# PIC32MK0128MCA032 device description
Architecture: MIPS; Family: PIC32MK; Series: PIC32MK
Registers are 32-bit, read-write, no defined reset value unless marked. A register's access mark holds for its fields unless they carry their own. Offsets are from the block's base; [hi:lo] are bit positions; {n}, {i} and the like mark numbered series; 'fields as' and 'values as' point back to an identical list.

## ADCHS
Instances: ADCHS 0x1f887000 in periph_pb5_std
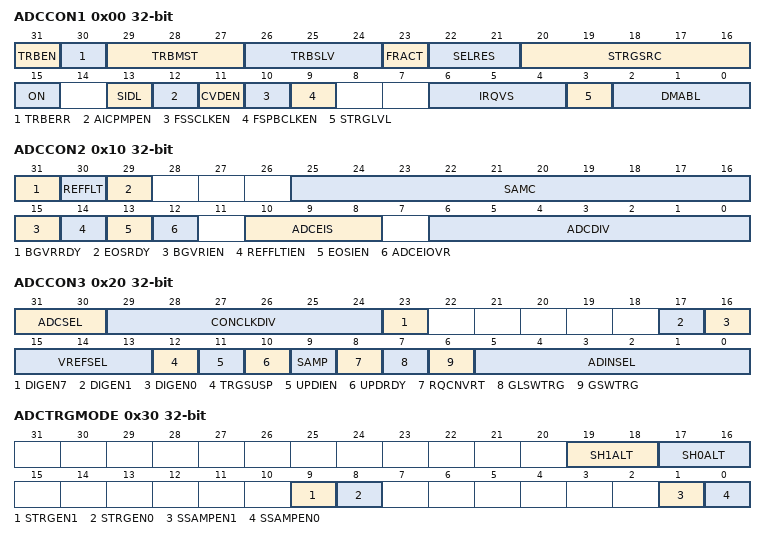
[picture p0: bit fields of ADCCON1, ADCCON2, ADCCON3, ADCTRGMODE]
0x00 ADCCON1 — ADC Control Register 1
  [31] TRBEN
  [30] TRBERR
  [29:27] TRBMST
  [26:24] TRBSLV
  [23] FRACT — Fractional Data Output Format bit
    1=Fractional; 0=Integer
  [22:21] SELRES — Shared ADC7 Resolution bits
    3=12 bits (default); 2=10 bits; 1=8 bits; 0=6 bits
  [20:16] STRGSRC — Scan Trigger Source Select bits
    {v}=PWM Generator {v-23} Current-Limit (v=24..27); 20=CTMU trip; {v}=Output Compare {v-15} period end (v=16..19); {v}=PWM Generator {v-9} trigger (v=10..13); 9=Secondary PWM time base; 8=Primary PWM time base; 7=General Purpose Timer5; 6=General Purpose Timer3; 5=General Purpose Timer1; 4=INT0; 2=Software level trigger; 1=Software edge trigger; 0=No Trigger
  [15] ON — ADC Module Enable bit
    1=ADC module is enabled; 0=ADC module is disabled
  [13] SIDL — Stop in Idle Mode bit
    1=Discontinue module operation when device enters Idle mode; 0=Continue module operation in Idle mode
  [12] AICPMPEN — Analog Input Charge Pump Enable bit
    1=Analog input charge pump is enabled; 0=Analog input charge pump is disabled (default)
  [11] CVDEN — Capacitive Voltage Division Enable bit
    1=CVD operation is enabled; 0=CVD operation is disabled
  [10] FSSCLKEN — Fast Synchronous System Clock to ADC Control Clock bit
    1=Bypass synchronizer logic for DMA system clock to ADC control clocks; 0=Enable clock synchronizers for non-synchronized DMA to ADC clock sources
  [9] FSPBCLKEN — Fast Synchronous Peripheral Clock to ADC Control Clock bit
    1=Bypass synchronizer logic for peripheral clock to ADC control clocks; 0=Enable clock synchronizers for non-synchronized peripheral clock to ADC control clocks
  [6:4] IRQVS — Interrupt Vector Shift bits
    {v}=Shift x left {v} bit position (v=0..7)
  [3] STRGLVL — Scan Trigger High Level/Positive Edge Sensitivity bit
    1=Scan trigger is high level sensitive. Once STRIG mode is selected the scan trigger will continue for all selected analog inputs; 0=Scan trigger is positive edge sensitive. Once STRIG mode is selected only a single scan trigger will be generated which will complete the scan of all selected analog inputs. (TRGSRCx in the ADCTRGx register)
  [2:0] DMABL — DMA to System RAM Buffer Length Size bits
    7=Allocates 128 locations in system memory to each analog input; 6=Allocates 64 locations in system memory to each analog input; 5=Allocates 32 locations in system memory to each analog input; 4=Allocates 16 locations in system memory to each analog input; 3=Allocates 8 locations in system memory to each analog input; 2=Allocates 4 locations in system memory to each analog input; 1=Allocates 2 locations in system memory to each analog input; 0=Allocates 1 location in system memory to each analog input
0x10 ADCCON2 — ADC Control Register 2
  [31] BGVRRDY — Band Gap Voltage/ADC Reference Voltage Status bit
    1=Both band gap voltage and ADC reference voltages (Vref) are ready; 0=Either or both band gap voltage and ADC reference voltages (Vref) are not ready
  [30] REFFLT — Band Gap/ Vref / AVdd BOR Fault Status bit
    1=Fault in band gap or the Vref voltage while the ON bit (ADCCON1) was set. Most likely a band gap or Vref fault will be caused by a BOR of the analog Vdd supply.; 0=Band gap and Vref voltage are working properly
  [29] EOSRDY — End of Scan Interrupt Status bit
    1=All analog inputs are considered for scanning through the scan trigger (all analog inputs specified in the ADCCSS1 and ADCCSS2 registers) have completed scanning; 0=Scanning has not completed
  [25:16] SAMC — Sample Time for the Shared ADC (ADC7) bits
    0x3ff=1025 Tad; 1=3 Tad; 0=2 Tad
  [15] BGVRIEN — Band Gap/ Vref Voltage Ready Interrupt Enable bit
    1=Interrupt will be generated when the BGVRDDY bit is set; 0=No interrupt is generated when the BGVRRDY bit is set
  [14] REFFLTIEN — Band Gap/ Vref Voltage Fault Interrupt Enable bit
    1=Interrupt will be generated when the REFFLT bit is set; 0=No interrupt is generated when the REFFLT bit is set
  [13] EOSIEN — End of Scan Interrupt Enable bit
    1=Interrupt will be generated when EOSRDY bit is set; 0=No interrupt is generated when the EOSRDY bit is set
  [12] ADCEIOVR — Early Interrupt Request Override bit
    1=Early interrupt generation is overridden and interrupt generation is controlled by the ADCGIRQEN1 and ADCGIRQEN2 registers; 0=Early interrupt generation is not overridden and interrupt generation is controlled by the ADCEIEN1 and ADCEIEN2 registers
  [10:8] ADCEIS — Shared ADC Early Interrupt Select bits
    {v}=The data ready interrupt is generated {v+1} ADC clocks prior to end of conversion (v=2..7); 1=The data ready interrupt is generated 2 ADC module clocks prior to end of conversion; 0=The data ready interrupt is generated 1 ADC module clock prior to end of conversion
  [6:0] ADCDIV — Shared ADC Clock Divider bits
    127=254 * Tq = Tad; 3=6 * Tq = Tad; 2=4 * Tq = Tad; 1=2 * Tq = Tad
0x20 ADCCON3 — ADC Control Register 3
  [31:30] ADCSEL — Analog-to-Digital Clock Source bits
    3=SYSCLK (Required if using DMA for ADC); 2=REFCLK3; 1=FRC; 0=SYSCLK
  [29:24] CONCLKDIV — Analog-to-Digital Control Clock Divider bits
    63=126 * Tclk = Tq; 3=6 * Tclk = Tq; 2=4 * Tclk = Tq; 1=2 * Tclk = Tq; 0=Tclk = Tq
  [23] DIGEN7 — ADC2 Digital Enable bit
    1=ADC2 is digital enabled (required for active operation); 0=ADC2 is digital disabled (power-saving mode)
  [17] DIGEN1 — ADC1 Digital Enable bit
    1=ADC1 is digital enabled (required for active operation); 0=ADC1 is digital disabled (power-saving mode)
  [16] DIGEN0 — ADC0 Digital Enable bit
    1=ADC0 is digital enabled (required for active operation); 0=ADC0 is digital disabled (power-saving mode)
  [15:13] VREFSEL — Voltage Reference Input Selection bits
    3=ADC VREFH is VREF+, ADC VREFL is VREF-; 2=ADC VREFH is AVDD, ADC VREFL is VREF-; 1=ADC VREFH is VREF+, ADC VREFL is AVSS; 0=ADC VREFH is AVDD, ADC VREFL is AVSS
  [12] TRGSUSP — Trigger Suspend bit
    1=Triggers are blocked from starting a new analog-to-digital conversion; 0=Triggers are not blocked
  [11] UPDIEN — Update Ready Interrupt Enable bit
    1=Interrupt will be generated when the UPDRDY bit is set by hardware; 0=No interrupt is generated
  [10] UPDRDY — ADC Update Ready Status bit
    1=ADC SFRs can be updated; 0=ADC SFRs cannot be updated
  [9] SAMP — Shared ADC7 Analog Input Sampling Enable bit
    1=The ADC S&H amplifier is sampling; 0=The ADC S&H amplifier is holding
  [8] RQCNVRT — Individual ADC Input Conversion Request bit
    1=Trigger the conversion of the selected ADC input as specified by the ADINSEL bits; 0=Do not trigger the conversion
  [7] GLSWTRG — Global Level Software Trigger bit
    1=Trigger conversion for ADC inputs that have selected the GLSWTRG bit as the trigger signal; 0=Do not trigger an analog-to-digital conversion
  [6] GSWTRG — Global Software Trigger bit
    1=Trigger conversion for ADC inputs that have selected the GSWTRG bit as either through the associated TRGSRC bits in the ADCTRGx registers or through the STRGSRC(4:0) bits in the ADCCON1 register the trigger signal
  [5:0] ADINSEL — Analog Input Select bits
    53=CTMU Temperature Sensor (internal AN53); 50=IVref 1.2V (internal AN50); {v}=AN{v} (v=0..17)
0x30 ADCTRGMODE — ADC Triggering Mode for Dedicated ADC Register
  [19:18] SH1ALT — ADC1 Analog Input Select bit
    3=AN16; 2=AN5; 1=AN3; 0=AN1
  [17:16] SH0ALT — ADC0 Analog Input Select bit
    3=AN6; 2=AN4; 1=AN13; 0=AN0
  [9] STRGEN1 — ADC1 Presynchronized Triggers bit
    1=ADC1 uses presynchronized triggers; 0=ADC1 does not use presynchronized triggers
  [8] STRGEN0 — ADC0 Presynchronized Triggers bit
    1=ADC0 uses presynchronized triggers; 0=ADC0 does not use presynchronized triggers
  [1] SSAMPEN1 — ADC1 Synchronous Sampling bit
    1=ADC1 uses synchronous sampling for the first sample after being idle or disabled; 0=ADC1 does not use synchronous sampling
  [0] SSAMPEN0 — ADC0 Synchronous Sampling bit
    1=ADC0 uses synchronous sampling for the first sample after being idle or disabled; 0=ADC0 does not use synchronous sampling
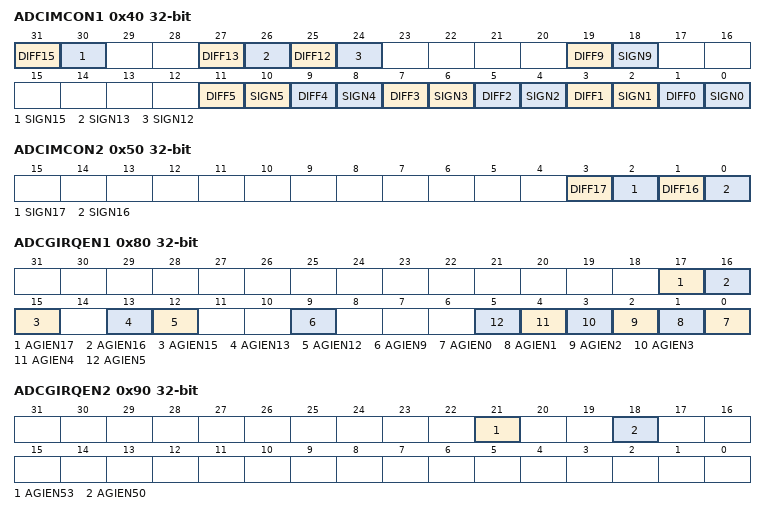
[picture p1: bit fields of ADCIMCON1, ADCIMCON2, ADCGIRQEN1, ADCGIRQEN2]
0x40 ADCIMCON1 — ADC Input Mode Control Register 1
  [31] DIFF15 — AN15 Mode bit
    1=Selects AN15 differential input pair as AN15+ and AN1-; 0=AN15 is using Single-ended mode
  [30] SIGN15 — AN15 Signed Data Mode bit
    1=AN15 is using Signed Data mode; 0=AN15 is using Unsigned Data mode
  [27] DIFF13 — AN13 Mode bit
    1=Selects AN13 differential input pair as AN13+ and AN1-; 0=AN13 is using Single-ended mode
  [26] SIGN13 — AN13 Signed Data Mode bit
    1=AN13 is using Signed Data mode; 0=AN13 is using Unsigned Data mode
  [25] DIFF12 — AN12 Mode bit
    1=Selects AN12 differential input pair as AN12+ and AN1-; 0=AN12 is using Single-ended mode
  [24] SIGN12 — AN12 Signed Data Mode bit
    1=AN12 is using Signed Data mode; 0=AN12 is using Unsigned Data mode
  [19] DIFF9 — AN9 Mode bit
    1=Selects AN9 differential input pair as AN9+ and AN1-; 0=AN9 is using Single-ended mode
  [18] SIGN9 — AN9 Signed Data Mode bit
    1=AN9 is using Signed Data mode; 0=AN9 is using Unsigned Data mode
  [11] DIFF5 — AN5 Mode bit
    1=Selects AN5 differential input pair as AN5+ and AN11-; 0=AN5 is using Single-ended mode
  [2n] SIGN{n} (n=0..5) — AN{n} Signed Data Mode bit
    1=AN{n} is using Signed Data mode; 0=AN{n} is using Unsigned Data mode
  [9] DIFF4 — AN4 Mode bit
    1=Selects AN4 differential input pair as AN4+ and AN10-; 0=AN4 is using Single-ended mode
  [7] DIFF3 — AN3 Mode bit
    1=Selects AN3 differential input pair as AN3+ and AN27-; 0=AN3 is using Single-ended mode
  [5] DIFF2 — AN2 Mode bit
    1=Selects AN2 differential input pair as AN2+ and AN8-; 0=AN2 is using Single-ended mode
  [3] DIFF1 — AN1 Mode bit
    1=Selects AN1 differential input pair as AN1+ and AN7-; 0=AN1 is using Single-ended mode
  [1] DIFF0 — AN0 Mode bit
    1=Selects AN0 differential input pair as AN0+ and AN6-; 0=AN0 is using Single-ended mode
0x50 ADCIMCON2 — ADC Input Mode Control Register 2
  [3] DIFF17 — AN17 Mode bit
    1=Selects AN17 differential pair input as AN17+ and AN1-; 0=AN17 is using Single-ended mode
  [2] SIGN17 — AN17 Signed Data Mode bit
    1=AN17 is using Signed Data mode; 0=AN17 is using Unsigned Data mode
  [1] DIFF16 — AN16 Mode bit
    1=Selects AN16 differential pair input as AN16+ and AN1-; 0=AN16 is using Single-ended mode
  [0] SIGN16 — AN16 Signed Data Mode bit
    1=AN16 is using Signed Data mode; 0=AN16 is using Unsigned Data mode
0x80 ADCGIRQEN1 — ADC Global Interrupt Enable Register 1
  [all] fields
    1=Interrupts are enabled for the selected analog input. The interrupt is generated after the converted data is ready (indicated by the AIRDYx bit of the ADCDSTAT1 register); 0=Interrupts are disabled
  [17] AGIEN17 — ADC Global Interrupt Enable bit
  [16] AGIEN16 — ADC Global Interrupt Enable bit
  [15] AGIEN15 — ADC Global Interrupt Enable bit
  [13] AGIEN13 — ADC Global Interrupt Enable bit
  [12] AGIEN12 — ADC Global Interrupt Enable bit
  [9] AGIEN9 — ADC Global Interrupt Enable bit
  [n] AGIEN{n} (n=0..5) — ADC Global Interrupt Enable bit
0x90 ADCGIRQEN2 — ADC Global Interrupt Enable Register 2
  [21] AGIEN53 — ADC Global Interrupt Enable bit
    values as the fields of ADCGIRQEN1
  [18] AGIEN50 — ADC Global Interrupt Enable bit
    values as the fields of ADCGIRQEN1
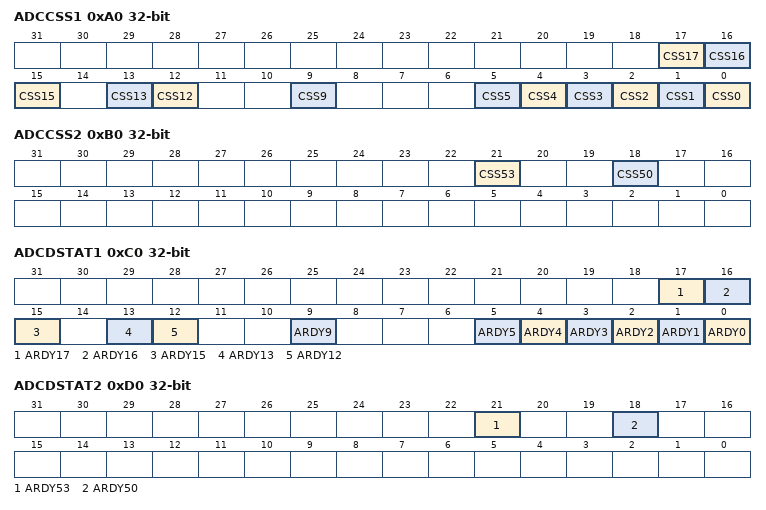
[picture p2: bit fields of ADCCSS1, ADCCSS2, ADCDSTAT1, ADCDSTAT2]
0xA0 ADCCSS1 — ADC Common Scan Select Register 1
  [all] fields
    1=Select ANx for input scan (i.e.ANx = CSSx and scan is sequential starting with the lowest to highest enabled CSSx analog input pin); 0=Skip ANx for input scan
  [17] CSS17 — Analog Common Scan Select bits
  [16] CSS16 — Analog Common Scan Select bits
  [15] CSS15 — Analog Common Scan Select bits
  [13] CSS13 — Analog Common Scan Select bits
  [12] CSS12 — Analog Common Scan Select bits
  [9] CSS9 — Analog Common Scan Select bits
  [n] CSS{n} (n=0..5) — Analog Common Scan Select bits
0xB0 ADCCSS2 — ADC Common Scan Select Register 2
  [21] CSS53 — Analog Common Scan Select bits
    values as the fields of ADCCSS1
  [18] CSS50 — Analog Common Scan Select bits
    values as the fields of ADCCSS1
0xC0 ADCDSTAT1 ro — ADC Data Ready Status Register 1
  [all] fields
    1=This bit is set when converted data is ready in the data register; 0=This bit is cleared when the associated data register is read
  [17] ARDY17 — Conversion Data Ready for Corresponding Analog Input Ready bits
  [16] ARDY16 — Conversion Data Ready for Corresponding Analog Input Ready bits
  [15] ARDY15 — Conversion Data Ready for Corresponding Analog Input Ready bits
  [13] ARDY13 — Conversion Data Ready for Corresponding Analog Input Ready bits
  [12] ARDY12 — Conversion Data Ready for Corresponding Analog Input Ready bits
  [9] ARDY9 — Conversion Data Ready for Corresponding Analog Input Ready bits
  [n] ARDY{n} (n=0..5) — Conversion Data Ready for Corresponding Analog Input Ready bits
0xD0 ADCDSTAT2 ro
  [21] ARDY53 — Conversion Data Ready for Corresponding Analog Input Ready bits
    values as the fields of ADCDSTAT1
  [18] ARDY50 — Conversion Data Ready for Corresponding Analog Input Ready bits
    values as the fields of ADCDSTAT1
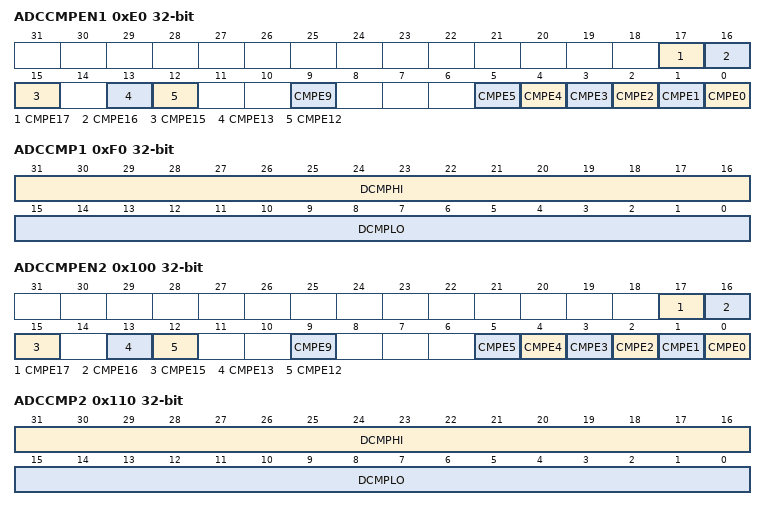
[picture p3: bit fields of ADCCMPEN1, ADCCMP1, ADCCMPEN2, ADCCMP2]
0xE0 ADCCMPEN1 — ADC Digital Comparator 'x' Enable Register ('x' = 1 through 4)
  [17] CMPE17, [16] CMPE16, [15] CMPE15, [13] CMPE13, [12] CMPE12, [9] CMPE9, [n] CMPE{n} (n=0..5)
0xF0 ADCCMP1
  [31:16] DCMPHI, [15:0] DCMPLO
0x100 ADCCMPEN2 — ADC Digital Comparator 'x' Enable Register ('x' = 1 through 4)
  fields as ADCCMPEN1
0x110 ADCCMP2
  [31:16] DCMPHI, [15:0] DCMPLO
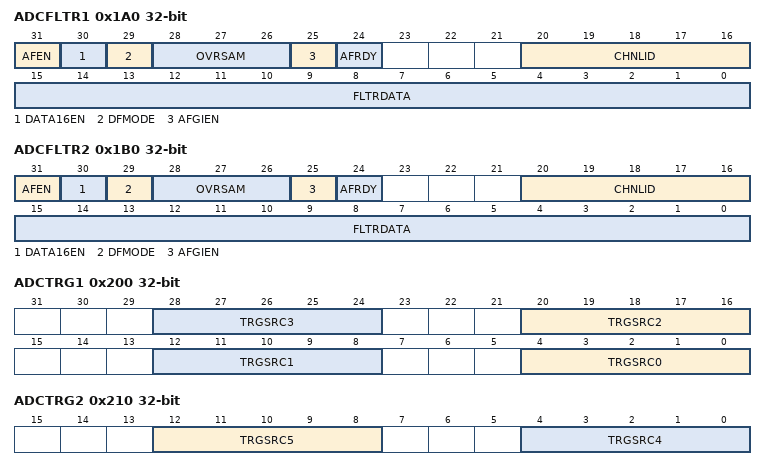
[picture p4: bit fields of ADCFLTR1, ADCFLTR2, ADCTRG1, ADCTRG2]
0x1A0 ADCFLTR1 — ADC Digital Filter Register
  [31] AFEN — Digital Filter 'x' Enable bit
    1=Digital filter is enabled; 0=Digital filter is disabled and the AFRDY status bit is cleared
  [30] DATA16EN — Filter Significant Data Length bit
    1=All 16 bits of the filter output data are significant; 0=Only the first 12 bits are significant
  [29] DFMODE — ADC Filter Mode bit
    1=Filter x works in Averaging mode; 0=Filter x works in Oversampling Filter mode (default)
  [28:26] OVRSAM — Oversampling Filter Ratio bits
    7=(If DFMODE is 0) 128 samples (shift sum 3 bits to right output data is in 15.1 format) / (If DFMODE is 1) 256 samples (256 samples to be averaged); 6=(If DFMODE is 0) 32 samples (shift sum 2 bits to right output data is in 14.1 format) / (If DFMODE is 1) 128 samples (128 samples to be averaged); 5=(If DFMODE is 0) 8 samples (shift sum 1 bit to right output data is in 13.1 format) / (If DFMODE is 1) 64 samples (64 samples to be averaged); 4=(If DFMODE is 0) 2 samples (shift sum 0 bits to right output data is in 12.1 format) / (If DFMODE is 1) 32 samples (32 samples to be averaged); 3=(If DFMODE is 0) 256 samples (shift sum 4 bits to right output data is 16 bits) / (If DFMODE is 1) 16 samples (16 samples to be averaged); 2=(If DFMODE is 0) 64 samples (shift sum 3 bits to right output data is 15 bits) / (If DFMODE is 1) 8 samples (8 samples to be averaged); 1=(If DFMODE is 0) 16 samples (shift sum 2 bits to right output data is 14 bits) / (If DFMODE is 1) 4 samples (4 samples to be averaged); 0=(If DFMODE is 0) 4 samples (shift sum 1 bit to right output data is 13 bits) / (If DFMODE is 1) 2 samples (2 samples to be averaged)
  [25] AFGIEN — Digital Filter 'x' Interrupt Enable bit
    1=Digital filter interrupt is enabled and is generated by the AFRDY status bit; 0=Digital filter is disabled
  [24] AFRDY — Digital Filter 'x' Data Ready Status bit
    1=Data is ready in the FLTRDATA bits; 0=Data is not ready
  [20:16] CHNLID — Digital Filter Analog Input Selection bits
    {v}=AN{v} input (v=6..17); {v}=ADC{v} Module (v=0..5)
  [15:0] FLTRDATA
0x1B0 ADCFLTR2 — ADC Digital Filter Register
  fields as ADCFLTR1
0x200 ADCTRG1 — ADC Trigger Source 1 Register
  [all] fields
    {v}=PWM Generator {v-23} Current-Limit (v=24..27); {v}=Output Compare {v-15} (Rising Edge Only) (v=16..19); {v}=PWM Generator {v-9} trigger (v=10..13); 9=Secondary Special Event trigger; 8=Primary Special Event trigger; 7=General Purpose Timer5; 6=General Purpose Timer3; 5=General Purpose Timer1; 4=INT0; 3=Scan trigger; 2=Software level trigger; 1=Software edge trigger; 0=No Trigger
  [8n+4:8n] TRGSRC{n} (n=0..3) — Trigger Source for Conversion of ADC{n} Module Select bits
0x210 ADCTRG2 — ADC Trigger Source 2 Register
  [12:8] TRGSRC5 — Trigger Source for Conversion of ADC5 Module Select bits
    {v}=PWM Generator {v-23} Current-Limit (v=24..27); 20=CTMU trip; {v}=Output Compare {v-15} (Rising Edge Only) (v=16..19); {v}=PWM Generator {v-9} trigger (v=10..13); 9=Secondary Special Event trigger; 8=Primary Special Event trigger; 7=General Purpose Timer5; 6=General Purpose Timer3; 5=General Purpose Timer1; 4=INT0; 3=Scan trigger; 2=Software level trigger; 1=Software edge trigger; 0=No Trigger
  [4:0] TRGSRC4 — Trigger Source for Conversion of ADC4 Module Select bits
    values as TRGSRC5
0x220 ADCTRG3 — ADC Trigger Source 3 Register
  [12:8] TRGSRC9 — Trigger Source for Conversion of Analog Input AN9 Select bits
    values as ADCTRG2.TRGSRC5
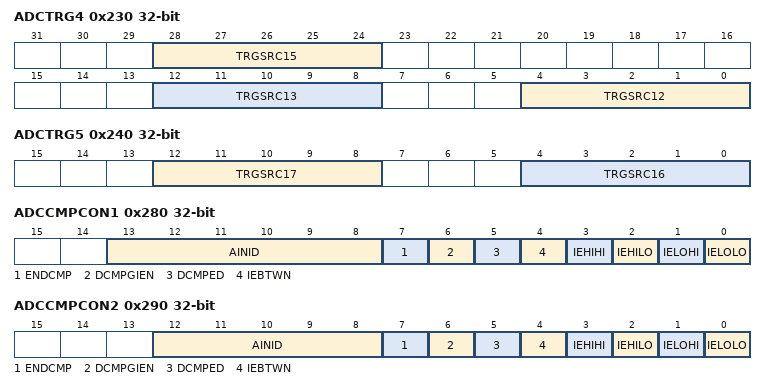
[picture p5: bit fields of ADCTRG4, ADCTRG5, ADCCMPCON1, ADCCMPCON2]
0x230 ADCTRG4 — ADC Trigger Source 4 Register
  [all] fields
    values as ADCTRG2.TRGSRC5
  [28:24] TRGSRC15 — Trigger Source for Conversion of Analog Input AN15 Select bits
  [12:8] TRGSRC13 — Trigger Source for Conversion of Analog Input AN13 Select bits
  [4:0] TRGSRC12 — Trigger Source for Conversion of Analog Input AN12 Select bits
0x240 ADCTRG5 — ADC Trigger Source 5 Register
  [12:8] TRGSRC17 — Trigger Source for Conversion of Analog Input AN17 Select bits
    values as ADCTRG2.TRGSRC5
  [4:0] TRGSRC16 — Trigger Source for Conversion of Analog Input AN16 Select bits
    values as ADCTRG2.TRGSRC5
0x280 ADCCMPCON1 — ADC Digital Comparator 1 Control Register
  [13:8] AINID — Digital Comparator 1 Analog Input Identification bits
    53=Internal AN53 (CTMU temperature sensor); 50=Internal AN50 (IVref 1.2V); {v}=AN{v} is being monitored (v=0..17)
  [7] ENDCMP — Digital Comparator 1 Enable bit
    1=Digital Comparator 1 is enabled; 0=Digital Comparator 1 is not enabled
  [6] DCMPGIEN — Digital Comparator 1 Global Interrupt Enable bit
    1=A Digital Comparator 1 interrupt is generated when the DCMPED status bit (ADCCMP0CON) is set; 0=A Digital Comparator 1 interrupt is disabled
  [5] DCMPED — Digital Comparator 1 Output True Event Status bit
    1=Digital Comparator 1 output true event has occurred (output of Comparator is 1); 0=Digital Comparator 1 output is false (output of comparator is 0)
  [4] IEBTWN — Between Low/High Digital Comparator 1 Event bit
    1=Generate a digital comparator event when DCMPLO less than DATA less than DCMPHI; 0=Do not generate a digital comparator event
  [3] IEHIHI — High/High Digital Comparator 0 Event bit
    1=Generate a Digital Comparator 0 Event when DCMPHI less than DATA; 0=Do not generate an event
  [2] IEHILO — High/Low Digital Comparator 0 Event bit
    1=Generate a Digital Comparator 0 Event when DATA less than DCMPHI; 0=Do not generate an event
  [1] IELOHI — Low/High Digital Comparator 0 Event bit
    1=Generate a Digital Comparator 0 Event when DCMPLO less than DATA; 0=Do not generate an event
  [0] IELOLO — Low/Low Digital Comparator 0 Event bit
    1=Generate a Digital Comparator 0 Event when DATA less than DCMPLO; 0=Do not generate an event
0x290 ADCCMPCON2 — ADC Digital Comparator 'x' Control Register
  [12:8] AINID — Digital Comparator 'x' Analog Input Identification bits
    {v}=AN{v} (v=0..17)
  [7] ENDCMP — Digital Comparator 'x' Enable bit
    1=Digital Comparator x is enabled; 0=Digital Comparator x is not enabled
  [6] DCMPGIEN — Digital Comparator 'x' Global Interrupt Enable bit
    1=A Digital Comparator x interrupt is generated when the DCMPED status bit (ADCCMPxCON) is set; 0=A Digital Comparator x interrupt is disabled
  [5] DCMPED — Digital Comparator 'x' Output True Event Status bit
    1=Digital Comparator x output true event has occurred (output of Comparator is 1); 0=Digital Comparator x output is false (output of Comparator is 0)
  [4] IEBTWN — Between Low/High Digital Comparator x Event bit
    1=Generate a digital comparator event when the DCMPLO bits less than DATA bits less than DCMPHI bits; 0=Do not generate an event
  [3] IEHIHI — High/High Digital Comparator x Event bit
    1=Generate a Digital Comparator x Event when the DCMPHI bits less than or equal to DATA(31:0) bits; 0=Do not generate an event
  [2] IEHILO — High/Low Digital Comparator x Event bit
    1=Generate a Digital Comparator x Event when the DATA bits less than DCMPHI(15:0) bits; 0=Do not generate an event
  [1] IELOHI — Low/High Digital Comparator x Event bit
    1=Generate a Digital Comparator x Event when the DCMPLO bits less than DATA(31:0) bits; 0=Do not generate an event
  [0] IELOLO — Low/Low Digital Comparator x Event bit
    1=Generate a Digital Comparator x Event when the DATA bits less than DCMPLO(15:0) bits; 0=Do not generate an event
0x300 ADCBASE
  [15:0] ADCBASE
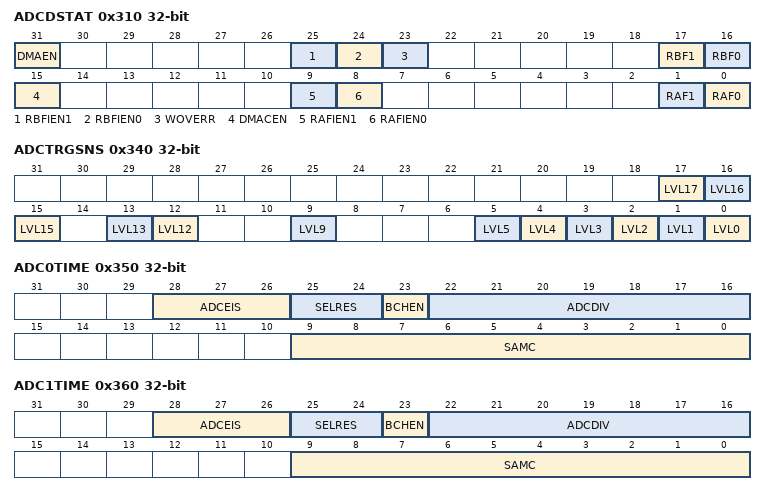
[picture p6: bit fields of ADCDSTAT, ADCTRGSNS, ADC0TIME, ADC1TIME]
0x310 ADCDSTAT — ADC DMA Status Register
  [31] DMAEN — Global ADC DMA Enable bit
    1=DMA interface is enabled; 0=DMA interface is disabled
  [25] RBFIEN1 — RAM DMA Buffer B Full Interrupt Enable bits for ADC1
    1=Enable ping-pong DMA Buffer B interrupt requests for ADC5-ADC0; 0=Disable ping-pong DMA Buffer B interrupt requests for ADC5-ADC0
  [24] RBFIEN0 — RAM DMA Buffer B Full Interrupt Enable bits for ADC0
    values as RBFIEN1
  [23] WOVERR
  [17] RBF1 — RAM DMA Buffer B Full Status bits for ADC1
    1=RAM DMA ping-pong Buffer B is full; 0=RAM DMA pin-pong Buffer B is not full
  [16] RBF0 — RAM DMA Buffer B Full Status bits for ADC0
    values as RBF1
  [15] DMACEN
  [9] RAFIEN1 — RAM DMA Buffer A Full Interrupt Enable bits for ADC1
    1=Enable ping-pong DMA Buffer A interrupt requests for ADC; 0=Disable ping-pong DMA Buffer A interrupt requests for ADC
  [8] RAFIEN0 — RAM DMA Buffer A Full Interrupt Enable bits for ADC0
    values as RAFIEN1
  [1] RAF1 — RAM DMA Ping-Pong Buffer A Full Status bits for ADC1
    1=RAM DMA ping-pong Buffer A is full; 0=RAM DMA ping-pong Buffer A is not full
  [0] RAF0 — RAM DMA Ping-Pong Buffer A Full Status bits for ADC0
    values as RAF1
0x320 ADCCNTB — ADC Channel Sample Count Base Address Register
0x330 ADCDMAB — ADC Channel Sample Count Base Address Register
0x340 ADCTRGSNS — ADC Trigger Level/Edge Sensitivity Register
  [all] fields
    1=Analog input is sensitive to the high level of its trigger (level sensitivity implies retriggering as long as the trigger signal remains high); 0=Analog input is sensitive to the positive edge of its trigger (this is the value after a reset)
  [17] LVL17 — Trigger Level and Edge Sensitivity bits
  [16] LVL16 — Trigger Level and Edge Sensitivity bits
  [15] LVL15 — Trigger Level and Edge Sensitivity bits
  [13] LVL13 — Trigger Level and Edge Sensitivity bits
  [12] LVL12 — Trigger Level and Edge Sensitivity bits
  [9] LVL9 — Trigger Level and Edge Sensitivity bits
  [n] LVL{n} (n=0..5) — Trigger Level and Edge Sensitivity bits
0x350 ADC0TIME — Dedicated High-Speed ADCx Timing Register ('x' = 0 through 5)
  [28:26] ADCEIS — ADCx Early Interrupt Select bits
    {v}=The data ready interrupt is generated {v+1} ADC clocks prior to the end of conversion (v=1..7); 0=The data ready interrupt is generated 1 ADC clock prior to the end of conversion
  [25:24] SELRES — ADCx Resolution Select bits
    3=12 bits; 2=10 bits; 1=8 bits; 0=6 bits
  [23] BCHEN — Buffer Channel Enable bit
    1=ADC data saved in DMA system ram buffer when DMAEN (ADCDSTAT) = 1; 0=ADC data must be read by CPU from appropriate ADC result register
  [22:16] ADCDIV — ADCx Clock Divisor bits
    127=254 * TQ = TADx; 3=6 * TQ = TADx; 2=4 * TQ = TADx; 1=2 * TQ = TADx
  [9:0] SAMC — ADCx Sample Time bits
    0x3ff=1025 TADx; 1=3 TADx; 0=2 TADx
0x360 ADC1TIME — Dedicated High-Speed ADCx Timing Register ('x' = 0 through 5)
  fields as ADC0TIME
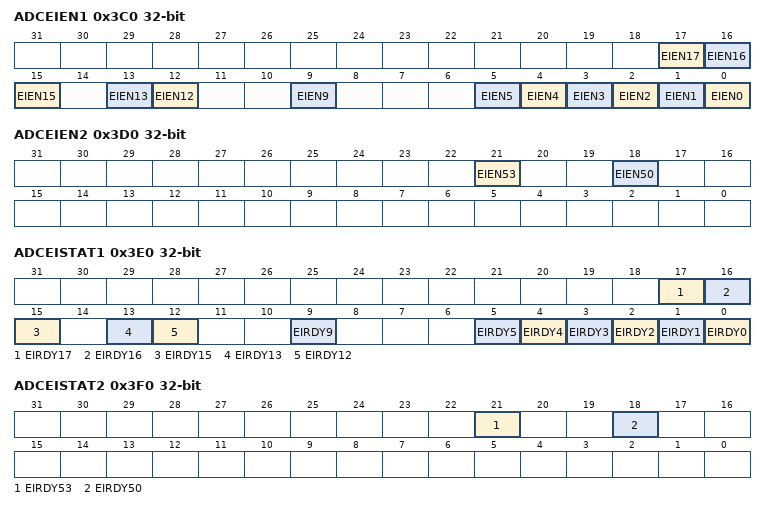
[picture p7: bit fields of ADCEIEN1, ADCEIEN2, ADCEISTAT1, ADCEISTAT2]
0x3C0 ADCEIEN1 — ADC Early Interrupt Enable Register 1
  [all] fields
    1=Early Interrupts are enabled for the selected analog input. The interrupt is generated after the early interrupt event occurs (indicated by the EIRDYx bit ('x' = 31-0) of the ADCEISTAT1 register); 0=Interrupts are disabled
  [17] EIEN17 — Early Interrupt Enable for Analog Input bits
  [16] EIEN16 — Early Interrupt Enable for Analog Input bits
  [15] EIEN15 — Early Interrupt Enable for Analog Input bits
  [13] EIEN13 — Early Interrupt Enable for Analog Input bits
  [12] EIEN12 — Early Interrupt Enable for Analog Input bits
  [9] EIEN9 — Early Interrupt Enable for Analog Input bits
  [n] EIEN{n} (n=0..5) — Early Interrupt Enable for Analog Input bits
0x3D0 ADCEIEN2
  [21] EIEN53 — Early Interrupt Enable for Analog Input bits
    values as the fields of ADCEIEN1
  [18] EIEN50 — Early Interrupt Enable for Analog Input bits
    values as the fields of ADCEIEN1
0x3E0 ADCEISTAT1 ro — ADC Early Interrupt Status Register 1
  [all] fields
    1=This bit is set when the early interrupt event occurs for the specified analog input. An interrupt will be generated if early interrupts are enabled in the ADCEIEN1 register. For the Class 1 analog inputs this bit will set as per the configuration of the ADCEIS bits in the ADCxTIME register. For the shared ADC module this bit will be set as per the configuration of the ADCEIS(2:0) bits in the ADCCON2 register.; 0=Interrupts are disabled
  [17] EIRDY17 — Early Interrupt for Corresponding Analog Input Ready bits
  [16] EIRDY16 — Early Interrupt for Corresponding Analog Input Ready bits
  [15] EIRDY15 — Early Interrupt for Corresponding Analog Input Ready bits
  [13] EIRDY13 — Early Interrupt for Corresponding Analog Input Ready bits
  [12] EIRDY12 — Early Interrupt for Corresponding Analog Input Ready bits
  [9] EIRDY9 — Early Interrupt for Corresponding Analog Input Ready bits
  [n] EIRDY{n} (n=0..5) — Early Interrupt for Corresponding Analog Input Ready bits
0x3F0 ADCEISTAT2 — ADC Early Interrupt Status Register 2
  [21] EIRDY53 — Early Interrupt for Corresponding Analog Input Ready bits
    values as the fields of ADCEISTAT1
  [18] EIRDY50 — Early Interrupt for Corresponding Analog Input Ready bits
    values as the fields of ADCEISTAT1
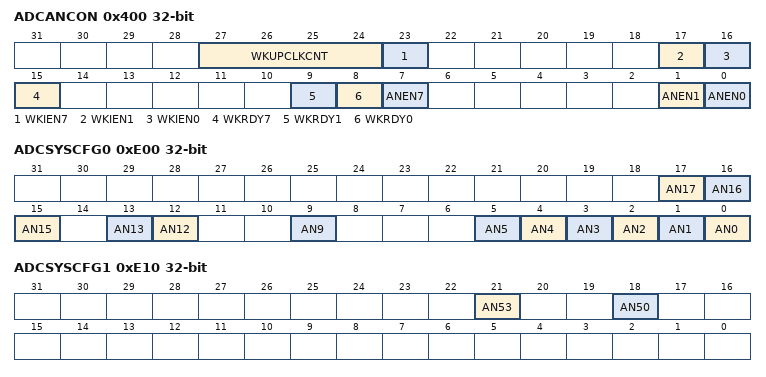
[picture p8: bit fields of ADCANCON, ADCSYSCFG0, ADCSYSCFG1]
0x400 ADCANCON — ADC Analog Warm-up Control Register
  [27:24] WKUPCLKCNT — Wake-up Clock Count bits
    15=2^15 = 32768 clocks; 14=2^14 = 16384 clocks; 13=2^13 = 8192 clocks; 12=2^12 = 4096 clocks; 11=2^11 = 2048 clocks; 10=2^10 = 1024 clocks; 9=2^9 = 512 clocks; 8=2^8 = 256 clocks; 7=2^7 = 128 clocks; 6=2^6 = 64 clocks; 5=2^5 = 32 clocks; 0=2^4 = 16 clocks
  [23] WKIEN7 — ADC Wake-up Interrupt Enable bit
    1=Enable interrupt and generate interrupt when the WKRDYx status bit is set; 0=Disable interrupt
  [17] WKIEN1 — ADC Wake-up Interrupt Enable bit
    values as WKIEN7
  [16] WKIEN0 — ADC Wake-up Interrupt Enable bit
    values as WKIEN7
  [15] WKRDY7 — ADC5-ADC0 Wake-up Status bit
    1=ADCx Analog and Bias circuitry ready after the wake-up count number 2WKUPEXP clocks after setting ANENx to 1; 0=ADCx Analog and Bias circuitry is not ready
  [9] WKRDY1 — ADC5-ADC0 Wake-up Status bit
    values as WKRDY7
  [8] WKRDY0 — ADC5-ADC0 Wake-up Status bit
    values as WKRDY7
  [7] ANEN7 — ADC Analog and Bias Circuitry Enable bits
    1=Analog and bias circuitry enabled. Once the analog and bias circuit is enabled the ADC module needs a warm-up time as defined by the WKUPCLKCNT bits.; 0=Analog and bias circuitry disabled
  [1] ANEN1 — ADC Analog and Bias Circuitry Enable bits
    values as ANEN7
  [0] ANEN0 — ADC Analog and Bias Circuitry Enable bits
    values as ANEN7
{0x600+0x10*i} ADCDATA{i} (i=0..5)
  [31:0] DATA
0x690 ADCDATA9
  [31:0] DATA
0x6C0 ADCDATA12
  [31:0] DATA
0x6D0 ADCDATA13
  [31:0] DATA
{0x600+0x10*i} ADCDATA{i} (i=15..17)
  [31:0] DATA
0x920 ADCDATA50
  [31:0] DATA
0x950 ADCDATA53
  [31:0] DATA
0xD00 ADC0CFG
  [31:0] ADCCFG
0xD10 ADC1CFG
  [31:0] ADCCFG
0xD70 ADC7CFG
  [31:0] ADCCFG
0xE00 ADCSYSCFG0 ro
  [17] AN17, [16] AN16, [15] AN15, [13] AN13, [12] AN12, [9] AN9, [n] AN{n} (n=0..5)
0xE10 ADCSYSCFG1 ro
  [21] AN53, [18] AN50
Value list ADCIMCON1__SIGN6: 1=AN6 is using Signed Data mode; 0=AN6 is using Unsigned Data mode
Value list ADCIMCON1__DIFF6: 1=Selects AN6 differential input pair as AN6+ and AN1-; 0=AN6 is using Single-ended mode
Value list ADCIMCON1__SIGN7: 1=AN7 is using Signed Data mode; 0=AN7 is using Unsigned Data mode
Value list ADCIMCON1__DIFF7: 1=Selects AN7 differential input pair as AN7+ and AN1-; 0=AN7 is using Single-ended mode
Value list ADCIMCON1__SIGN8: 1=AN8 is using Signed Data mode; 0=AN8 is using Unsigned Data mode
Value list ADCIMCON1__DIFF8: 1=Selects AN8 differential input pair as AN8+ and AN1-; 0=AN8 is using Single-ended mode
Value list ADCIMCON1__SIGN10: 1=AN10 is using Signed Data mode; 0=AN10 is using Unsigned Data mode
Value list ADCIMCON1__DIFF10: 1=Selects AN10 differential input pair as AN10+ and AN1-; 0=AN10 is using Single-ended mode
Value list ADCIMCON1__SIGN11: 1=AN11 is using Signed Data mode; 0=AN11 is using Unsigned Data mode
Value list ADCIMCON1__DIFF11: 1=Selects AN11 differential input pair as AN11+ and AN1-; 0=AN11 is using Single-ended mode
Value list ADCIMCON1__SIGN14: 1=AN14 is using Signed Data mode; 0=AN14 is using Unsigned Data mode
Value list ADCIMCON1__DIFF14: 1=Selects AN14 differential input pair as AN14+ and AN1-; 0=AN14 is using Single-ended mode
